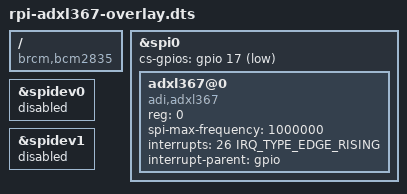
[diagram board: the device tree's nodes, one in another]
// SPDX-License-Identifier: GPL-2.0

/dts-v1/;
/plugin/;

#include <dt-bindings/gpio/gpio.h>
#include <dt-bindings/interrupt-controller/irq.h>

/ {
	compatible = "brcm,bcm2835", "brcm,bcm2708", "brcm,bcm2709", "brcm,bcm2711";
};

&spi0 {
	#address-cells = <1>;
	#size-cells = <0>;

	cs-gpios = <&gpio 17 GPIO_ACTIVE_LOW>;
	status = "okay";

	adxl367@0 {
		compatible = "adi,adxl367";
		reg = <0>;
		spi-max-frequency = <1000000>;
		interrupts = <26 IRQ_TYPE_EDGE_RISING>;
		interrupt-parent = <&gpio>;
	};
};

&spidev0 {
	status = "disabled";
};

&spidev1 {
	status = "disabled";
};
